# STM32MP153 register map
File version: 1.3
CPU: CM4 r0p1, little endian, no MPU, FPU, 4 interrupt priority bits
Registers are 32-bit, read-write, reset 0x0 unless marked. A register's access mark holds for its fields unless they carry their own. Offsets are from the block's base; [hi:lo] are bit positions; 'fields as' and 'values as' point back to an identical list.

## RCC (part 1 of 2)
Base 0x50000000
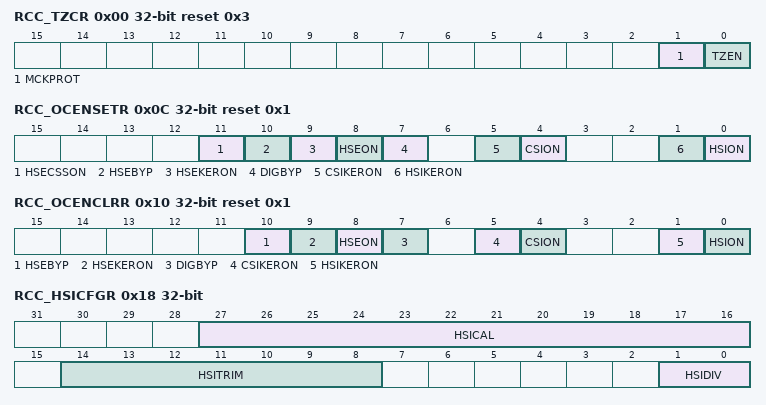
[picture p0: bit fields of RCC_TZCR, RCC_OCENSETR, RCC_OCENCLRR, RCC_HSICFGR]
0x00 RCC_TZCR reset 0x3 — This register is used to switch the RCC into secure mode. This register can only be accessed in secure mode.
  [1] MCKPROT, [0] TZEN
0x0C RCC_OCENSETR reset 0x1 — This register is used to control the oscillators.Writing to this register has no effect, writing will set the corresponding bits. Reading will give the effective values of each bit.If TZEN = MCKPROT = , this register can only be modified in secure mode. Write access to this register is not allowed during the clock restore sequence. See Section: The clock restore sequence description for details.
  [11] HSECSSON, [10] HSEBYP, [9] HSEKERON, [8] HSEON, [7] DIGBYP, [5] CSIKERON, [4] CSION, [1] HSIKERON, [0] HSION
0x10 RCC_OCENCLRR reset 0x1 — This register is used to control the oscillators.Writing to this register has no effect, writing will clear the corresponding bits. Reading will give the effective values of the enable bits.If TZEN = , this register can only be modified in secure mode. Write access to this register is not allowed during the clock restore sequence. See Section: The clock restore sequence description for details.
  [10] HSEBYP, [9] HSEKERON, [8] HSEON, [7] DIGBYP, [5] CSIKERON, [4] CSION, [1] HSIKERON, [0] HSION
0x18 RCC_HSICFGR access per field — This register is used to configure the HSI. If TZEN = , this register can only be modified in secure mode. Write access to this register is not allowed during the clock restore sequence. See Section: The clock restore sequence description for details.
  [27:16] HSICAL ro, [14:8] HSITRIM rw, [1:0] HSIDIV rw
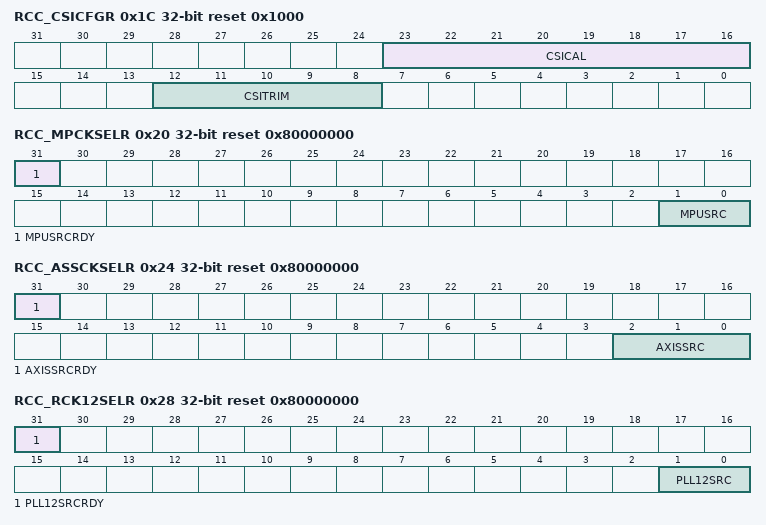
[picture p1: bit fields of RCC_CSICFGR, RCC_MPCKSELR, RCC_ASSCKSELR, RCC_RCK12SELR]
0x1C RCC_CSICFGR access per field reset 0x1000 — This register is used to fine-tune the CSI frequency. If TZEN = MCKPROT = , this register can only be modified in secure mode. Write access to this register is not allowed during the clock restore sequence. See The clock restore sequence description for details.
  [23:16] CSICAL ro, [12:8] CSITRIM rw
0x20 RCC_MPCKSELR access per field reset 0x80000000 — This register is used to select the clock source for the MPU. If TZEN = , this register can only be modified in secure mode. Write access to this register is not allowed during the clock restore sequence. See Section: The clock restore sequence description for details.
  [31] MPUSRCRDY ro, [1:0] MPUSRC rw
0x24 RCC_ASSCKSELR access per field reset 0x80000000 — This register is used to select the clock source for the AXI sub-system. If TZEN = , this register can only be modified in secure mode. Write access to this register is not allowed during the clock restore sequence. See Section: The clock restore sequence description for details.
  [31] AXISSRCRDY ro, [2:0] AXISSRC rw
0x28 RCC_RCK12SELR access per field reset 0x80000000 — This register is used to select the reference clock for PLL1 and PLL2. If TZEN = , this register can only be modified in secure mode. Write access to this register is not allowed during the clock restore sequence. See Section: The clock restore sequence description for details.
  [31] PLL12SRCRDY ro, [1:0] PLL12SRC rw
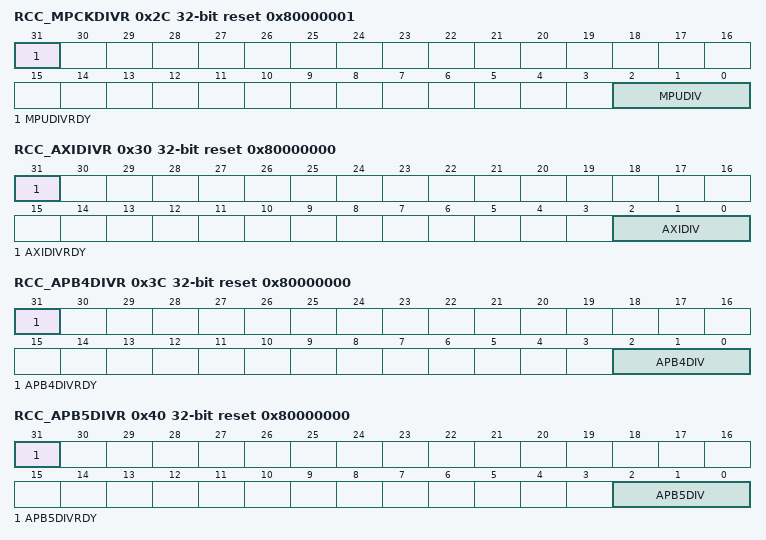
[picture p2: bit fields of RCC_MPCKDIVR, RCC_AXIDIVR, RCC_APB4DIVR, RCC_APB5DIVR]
0x2C RCC_MPCKDIVR access per field reset 0x80000001 — This register is used to control the MPU clock prescaler. Refer to Section: Sub-system clock generation for additional information. If TZEN = , this register can only be modified in secure mode.
  [31] MPUDIVRDY ro, [2:0] MPUDIV rw
0x30 RCC_AXIDIVR access per field reset 0x80000000 — This register is used to control the AXI Matrix clock prescaler. Refer to Section: Sub-system clock generation for additional information. If TZEN = , this register can only be modified in secure mode.
  [31] AXIDIVRDY ro, [2:0] AXIDIV rw
0x3C RCC_APB4DIVR access per field reset 0x80000000 — This register is used to control the APB4 clock divider. Refer to Section: Sub-system clock generation for additional information. If TZEN = , this register can only be modified in secure mode.
  [31] APB4DIVRDY ro, [2:0] APB4DIV rw
0x40 RCC_APB5DIVR access per field reset 0x80000000 — This register is used to control the APB5 clock divider. Refer to Section: Sub-system clock generation for additional information. If TZEN = , this register can only be modified in secure mode.
  [31] APB5DIVRDY ro, [2:0] APB5DIV rw
0x44 RCC_RTCDIVR — This register is used to divide the HSE clock for RTC. If TZEN = , this register can only be modified in secure mode.
  [5:0] RTCDIV
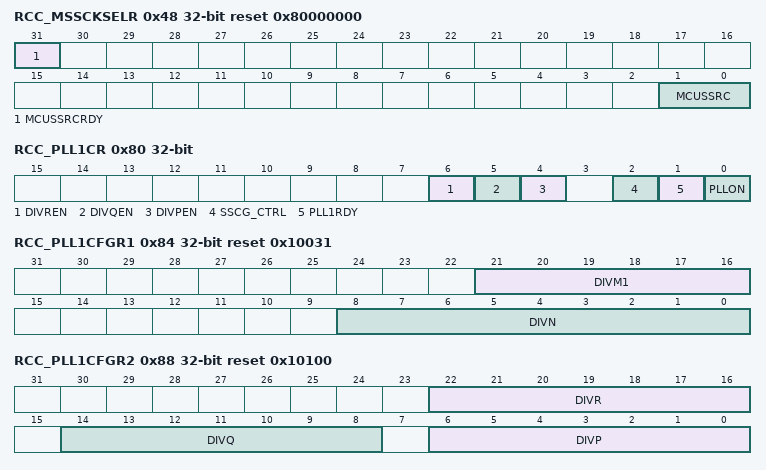
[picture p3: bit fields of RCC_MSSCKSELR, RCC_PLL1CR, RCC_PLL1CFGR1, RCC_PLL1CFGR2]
0x48 RCC_MSSCKSELR access per field reset 0x80000000 — This register is used to select the clock source for the MCU sub-system, including the MCU itself. If TZEN = MCKPROT = , this register can only be modified in secure mode. Write access to this register is not allowed during the clock restore sequence. See Section: The clock restore sequence description for details.
  [31] MCUSSRCRDY ro, [1:0] MCUSSRC rw
0x80 RCC_PLL1CR access per field — This register is used to control the PLL1. If TZEN = , this register can only be modified in secure mode. Write access to this register is not allowed during the clock restore sequence. See Section: The clock restore sequence description for details.
  [6] DIVREN rw, [5] DIVQEN rw, [4] DIVPEN rw, [2] SSCG_CTRL rw, [1] PLL1RDY ro, [0] PLLON rw
0x84 RCC_PLL1CFGR1 reset 0x10031 — This register is used to configure the PLL1. If TZEN = , this register can only be modified in secure mode. Write access to this register is not allowed during the clock restore sequence. See Section: The clock restore sequence description for details.
  [21:16] DIVM1, [8:0] DIVN
0x88 RCC_PLL1CFGR2 reset 0x10100 — This register is used to configure the PLL1. If TZEN = , this register can only be modified in secure mode. Write access to this register is not allowed during the clock restore sequence. See Section: The clock restore sequence description for details.
  [22:16] DIVR, [14:8] DIVQ, [6:0] DIVP
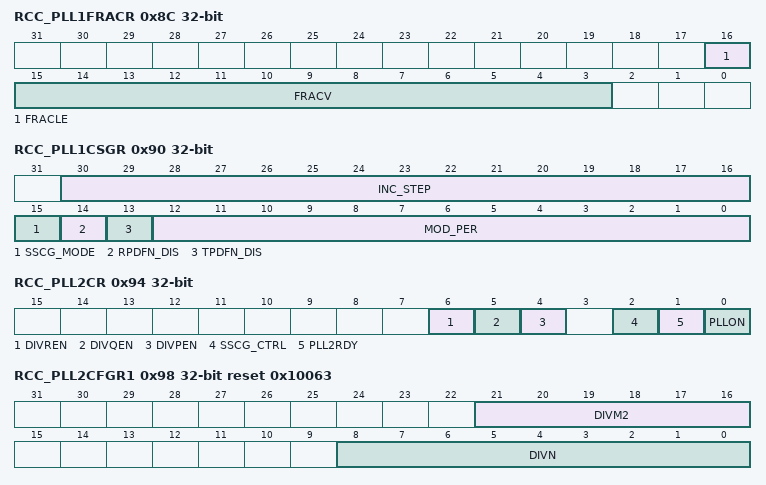
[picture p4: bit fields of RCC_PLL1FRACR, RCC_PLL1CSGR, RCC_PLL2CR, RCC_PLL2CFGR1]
0x8C RCC_PLL1FRACR — This register is used to fine-tune the frequency of the PLL1 VCO. If TZEN = , this register can only be modified in secure mode. Write access to this register is not allowed during the clock restore sequence. See Section: The clock restore sequence description for details.
  [16] FRACLE, [15:3] FRACV
0x90 RCC_PLL1CSGR — This register is used to configure the PLL1.It is not recommended to change the content of this register when the PLL1 is enabled (PLLON = ). Refer to Section: Using the PLLs in spread spectrum mode for details. If TZEN = , this register can only be modified in secure mode. Write access to this register is not allowed during the clock restore sequence. See Section: The clock restore sequence description for details.
  [30:16] INC_STEP, [15] SSCG_MODE, [14] RPDFN_DIS, [13] TPDFN_DIS, [12:0] MOD_PER
0x94 RCC_PLL2CR access per field — This register is used to control the PLL2. If TZEN = , this register can only be modified in secure mode. Write access to this register is not allowed during the clock restore sequence. See Section: The clock restore sequence description for details.
  [6] DIVREN rw, [5] DIVQEN rw, [4] DIVPEN rw, [2] SSCG_CTRL rw, [1] PLL2RDY ro, [0] PLLON rw
0x98 RCC_PLL2CFGR1 reset 0x10063 — This register is used to configure the PLL2. If TZEN = , this register can only be modified in secure mode. Write access to this register is not allowed during the clock restore sequence. See Section: The clock restore sequence description for details.
  [21:16] DIVM2, [8:0] DIVN
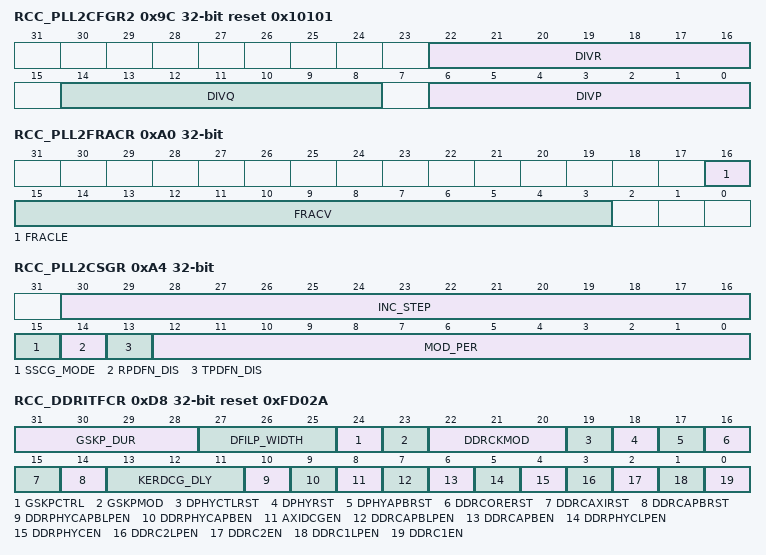
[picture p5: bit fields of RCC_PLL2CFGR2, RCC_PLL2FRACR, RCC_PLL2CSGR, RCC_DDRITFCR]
0x9C RCC_PLL2CFGR2 reset 0x10101 — This register is used to configure the PLL2. If TZEN = , this register can only be modified in secure mode. Write access to this register is not allowed during the clock restore sequence. See Section: The clock restore sequence description for details.
  [22:16] DIVR, [14:8] DIVQ, [6:0] DIVP
0xA0 RCC_PLL2FRACR — This register is used to fine-tune the frequency of the PLL2 VCO. If TZEN = , this register can only be modified in secure mode. Write access to this register is not allowed during the clock restore sequence. See Section: The clock restore sequence description for details.
  [16] FRACLE, [15:3] FRACV
0xA4 RCC_PLL2CSGR — This register is used to configure the PLL2. It is not recommended to change the content of this register when the PLL2 is enabled (PLLON = ). Refer to Section: Using the PLLs in spread spectrum mode for details. If TZEN = , this register can only be modified in secure mode. Write access to this register is not allowed during the clock restore sequence. See Section: The clock restore sequence description for details.
  fields as RCC_PLL1CSGR
0xC0 RCC_I2C46CKSELR — This register is used to control the selection of the kernel clock for the I2C4 and I2C6. Note that changing the clock source on-the-fly is allowed, and will not generate any timing violation, however the user has to ensure that both the previous and the new clock sources are present during the switching, and for the whole transition time. Refer to Section: Clock enabling delays. If TZEN = , this register can only be modified in secure mode.
  [2:0] I2C46SRC
0xC4 RCC_SPI6CKSELR — This register is used to control the selection of the kernel clock for the SPI6. Note that changing the clock source on-the-fly is allowed, and will not generate any timing violation, however the user has to ensure that both the previous and the new clock sources are present during the switching, and for the whole transition time. Refer to Section: Clock enabling delays. If TZEN = , this register can only be modified in secure mode.
  [2:0] SPI6SRC
0xC8 RCC_UART1CKSELR — This register is used to control the selection of the kernel clock for the USART1. Note that changing the clock source on-the-fly is allowed, and will not generate any timing violation, however the user has to ensure that both the previous and the new clock sources are present during the switching, and for the whole transition time. Refer to Section: Clock enabling delays. If TZEN = , this register can only be modified in secure mode.
  [2:0] UART1SRC
0xCC RCC_RNG1CKSELR — This register is used to control the selection of the kernel clock for the RNG1. Note that changing the clock source on-the-fly is allowed, and will not generate any timing violation, however the user has to ensure that both the previous and the new clock sources are present during the switching, and for the whole transition time. Refer to Section: Clock enabling delays. If TZEN = , this register can only be modified in secure mode.
  [1:0] RNG1SRC
0xD0 RCC_CPERCKSELR — This register is used to select an oscillator source as kernel clock for the per_ck clock. The per_ck clock is distributed to several peripherals. Refer to Section: Clock enabling delays.
  [1:0] CKPERSRC
0xD4 RCC_STGENCKSELR — This register is used to select the peripheral clock for the STGEN block. Note that this clock is used to provide a time reference for the application. Refer to Section: Clock enabling delays. If TZEN = , this register can only be modified in secure mode.
  [1:0] STGENSRC
0xD8 RCC_DDRITFCR reset 0xFD02A — This register is used to control the DDR interface, including the DDRC and DDRPHYC. If TZEN = , this register can only be modified in secure mode.
  [31:28] GSKP_DUR, [27:25] DFILP_WIDTH, [24] GSKPCTRL, [23] GSKPMOD, [22:20] DDRCKMOD, [19] DPHYCTLRST, [18] DPHYRST, [17] DPHYAPBRST, [16] DDRCORERST, [15] DDRCAXIRST, [14] DDRCAPBRST, [13:11] KERDCG_DLY, [10] DDRPHYCAPBLPEN, [9] DDRPHYCAPBEN, [8] AXIDCGEN, [7] DDRCAPBLPEN, [6] DDRCAPBEN, [5] DDRPHYCLPEN, [4] DDRPHYCEN, [3] DDRC2LPEN, [2] DDRC2EN, [1] DDRC1LPEN, [0] DDRC1EN
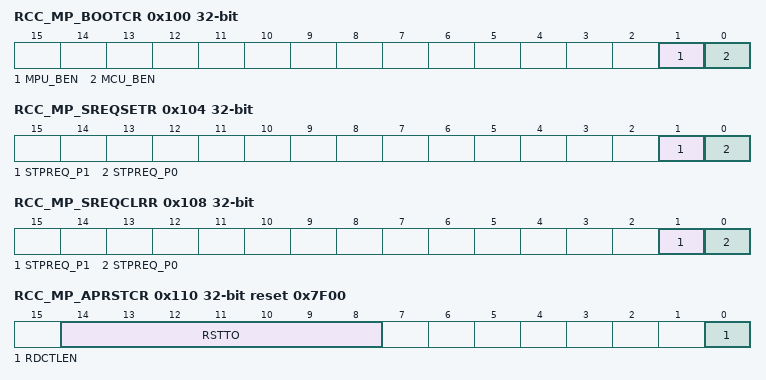
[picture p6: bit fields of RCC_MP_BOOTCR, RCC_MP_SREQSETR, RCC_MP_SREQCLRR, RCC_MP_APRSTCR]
0x100 RCC_MP_BOOTCR — This register is used to control the HOLD boot function when the system exits from Standby. Refer to Section: MCU HOLD_BOOT after processor reset. This register is reset when a system reset occurs, but not when the circuit exits from Standby (app_rst reset).If TZEN = , this register can only be modified in secure mode. This register can only be accessed by the MPU.
  [1] MPU_BEN, [0] MCU_BEN
0x104 RCC_MP_SREQSETR — Writing has no effect, reading will return the values of the bits. Writing a sets the corresponding bit to . The MCU cannot access to this register. If TZEN = , this register can only be modified in secure mode.
  [1] STPREQ_P1, [0] STPREQ_P0
0x108 RCC_MP_SREQCLRR — Writing has no effect, reading will return the effective values of the bits. Writing a sets the corresponding bit to . The MCU cannot access to this register. If TZEN = , this register can only be modified in secure mode.
  [1] STPREQ_P1, [0] STPREQ_P0
0x10C RCC_MP_GCR — The register contains global control bits. If TZEN = , this register can only be modified in secure mode.
  [0] BOOT_MCU
0x110 RCC_MP_APRSTCR reset 0x7F00 — This register is used to control the behavior of the warm reset. If TZEN = , this register can only be modified in secure mode.
  [14:8] RSTTO, [0] RDCTLEN
0x114 RCC_MP_APRSTSR ro — This register provides a status of the RDCTL. If TZEN = , this register can only be modified in secure mode.
  [14:8] RSTTOV
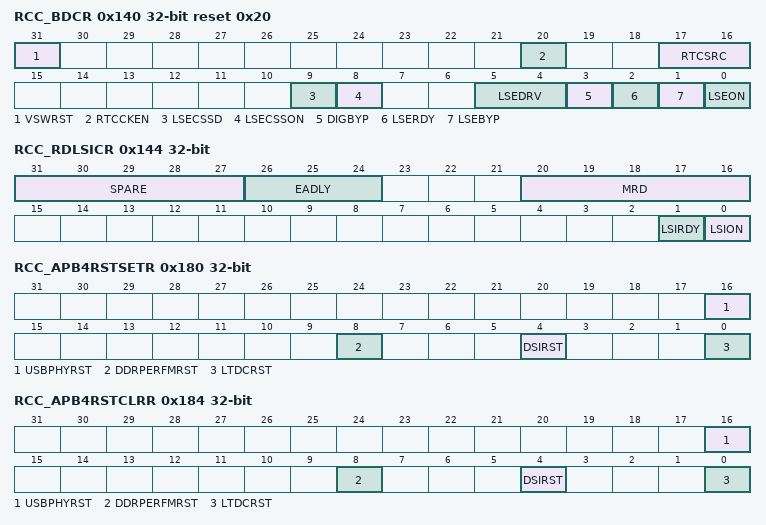
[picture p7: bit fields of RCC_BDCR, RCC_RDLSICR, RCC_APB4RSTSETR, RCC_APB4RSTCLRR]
0x140 RCC_BDCR access per field reset 0x20 — This register is used to control the LSE function. Wait states are inserted in case of successive write accesses to this register. The number of wait states may be up to 7 cycles of AHB4 clock.After a system reset, the register RCC_BDCR is write-protected. In order to modify this register, the DBP bit in the PWR control register 1 (PWR_CR1) has to be set to . Bits of RCC_BDCR register are only reset after a backup domain reset: nreset_vsw (see Section10.3.6: Backup domain reset). Any other internal or external reset will not have any effect on these bits.This register is located into the VSW domain. If TZEN = , this register can only be modified in secure mode.
  [31] VSWRST rw, [20] RTCCKEN rw, [17:16] RTCSRC ro, [9] LSECSSD ro, [8] LSECSSON rw, [5:4] LSEDRV rw, [3] DIGBYP ro, [2] LSERDY ro, [1] LSEBYP rw, [0] LSEON rw
0x144 RCC_RDLSICR access per field — This register is used to control the minimum NRST active duration and LSI function.0 to 7 wait states are inserted for word, half-word and byte accesses. Wait states are inserted in case of successive accesses to this register.This register is reset by the por_rst reset, and it is located into the VDD domain. If TZEN = , this register can only be modified in secure mode.
  [31:27] SPARE rw, [26:24] EADLY rw, [20:16] MRD rw, [1] LSIRDY ro, [0] LSION rw
0x180 RCC_APB4RSTSETR — This register is used to activate the reset of the corresponding peripheral. Writing has no effect, reading will return the effective values of the corresponding bits. Writing a activates the reset of the corresponding peripheral.
  [16] USBPHYRST, [8] DDRPERFMRST, [4] DSIRST, [0] LTDCRST
0x184 RCC_APB4RSTCLRR — This register is used to release the reset of the corresponding peripheral. Writing has no effect, reading will return the effective values of the corresponding bits. Writing a releases the reset of the corresponding peripheral.
  [16] USBPHYRST, [8] DDRPERFMRST, [4] DSIRST, [0] LTDCRST
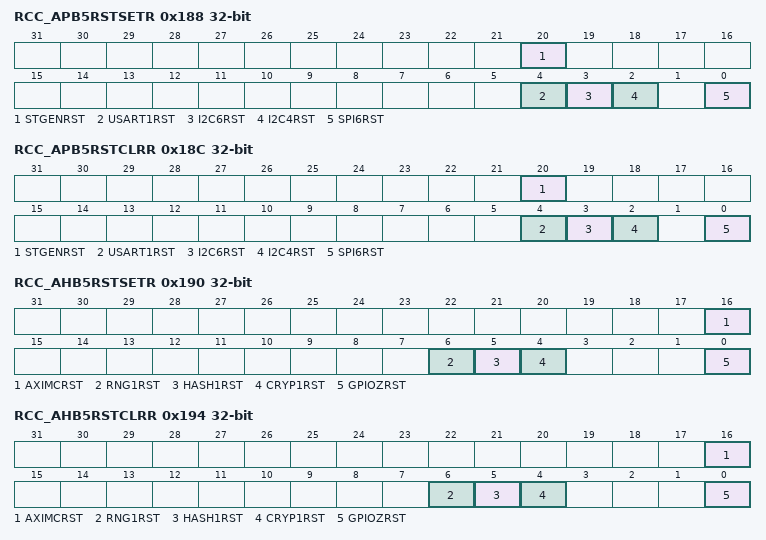
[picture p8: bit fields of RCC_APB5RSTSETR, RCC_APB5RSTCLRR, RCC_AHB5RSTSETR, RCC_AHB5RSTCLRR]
0x188 RCC_APB5RSTSETR — This register is used to activate the reset of the corresponding peripheral. Writing has no effect, reading will return the effective values of the corresponding bits. Writing a activates the reset of the corresponding peripheral. If TZEN = , this register can only be modified in secure mode.
  [20] STGENRST, [4] USART1RST, [3] I2C6RST, [2] I2C4RST, [0] SPI6RST
0x18C RCC_APB5RSTCLRR — This register is used to release the reset of the corresponding peripheral. Writing has no effect, reading will return the effective values of the corresponding bits. Writing a releases the reset of the corresponding peripheral. If TZEN = , this register can only be modified in secure mode.
  [20] STGENRST, [4] USART1RST, [3] I2C6RST, [2] I2C4RST, [0] SPI6RST
0x190 RCC_AHB5RSTSETR — This register is used to activate the reset of the corresponding peripheral. Writing has no effect, reading will return the effective values of the corresponding bits. Writing a activates the reset of the corresponding peripheral. If TZEN = , this register can only be modified in secure mode.
  [16] AXIMCRST, [6] RNG1RST, [5] HASH1RST, [4] CRYP1RST, [0] GPIOZRST
0x194 RCC_AHB5RSTCLRR — This register is used to release the reset of the corresponding peripheral. Writing has no effect, reading will return the effective values of the corresponding bits. Writing a releases the reset of the corresponding peripheral. If TZEN = , this register can only be modified in secure mode.
  [16] AXIMCRST, [6] RNG1RST, [5] HASH1RST, [4] CRYP1RST, [0] GPIOZRST
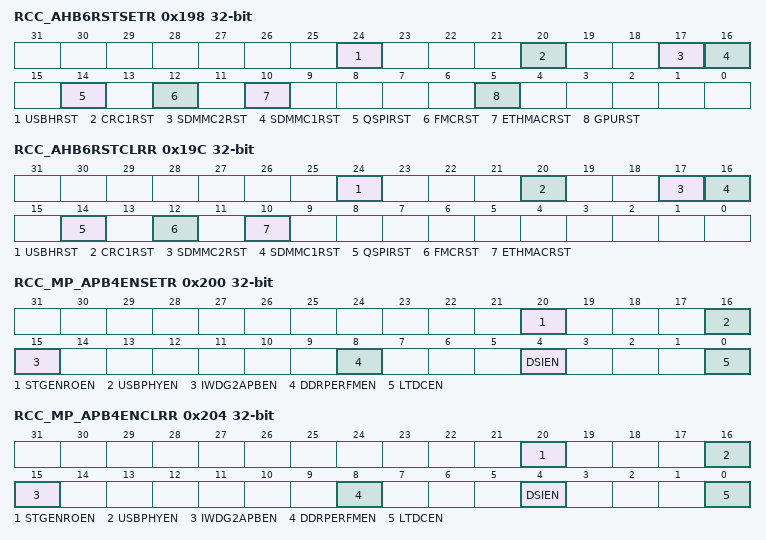
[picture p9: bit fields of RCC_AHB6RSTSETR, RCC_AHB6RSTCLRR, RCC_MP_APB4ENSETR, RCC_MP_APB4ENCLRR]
0x198 RCC_AHB6RSTSETR — This register is used to activate the reset of the corresponding peripheral. Writing has no effect, reading will return the effective values of the corresponding bits. Writing a activates the reset of the corresponding peripheral.
  [24] USBHRST, [20] CRC1RST, [17] SDMMC2RST, [16] SDMMC1RST, [14] QSPIRST, [12] FMCRST, [10] ETHMACRST, [5] GPURST
0x19C RCC_AHB6RSTCLRR — This register is used to release the reset of the corresponding peripheral. Writing has no effect, reading will return the effective values of the corresponding bits. Writing a releases the reset of the corresponding peripheral.
  [24] USBHRST, [20] CRC1RST, [17] SDMMC2RST, [16] SDMMC1RST, [14] QSPIRST, [12] FMCRST, [10] ETHMACRST
0x1A0 RCC_TZAHB6RSTSETR — This register is used to activate the reset of the corresponding peripheral. Writing has no effect, reading will return the effective values of the corresponding bits. Writing a activates the reset of the corresponding peripheral. If TZEN = , this register can only be modified in secure mode.
  [0] MDMARST
0x1A4 RCC_TZAHB6RSTCLRR — This register is used to release the reset of the corresponding peripheral. Writing has no effect, reading will return the effective values of the corresponding bits. Writing a releases the reset of the corresponding peripheral. If TZEN = , this register can only be modified in secure mode.
  [0] MDMARST
0x200 RCC_MP_APB4ENSETR — This register is used to set the peripheral clock enable bit of the corresponding peripheral to . It shall be used to allocate a peripheral to the MPU. Writing has no effect, reading will return the effective values of the corresponding bits. Writing a sets the corresponding bit to .
  [20] STGENROEN, [16] USBPHYEN, [15] IWDG2APBEN, [8] DDRPERFMEN, [4] DSIEN, [0] LTDCEN
0x204 RCC_MP_APB4ENCLRR — This register is used to clear the peripheral clock enable bit of the corresponding peripheral. It shall be used to deallocate a peripheral from MPU. Writing has no effect, reading will return the effective values of the corresponding bits. Writing a sets the corresponding bit to .
  fields as RCC_MP_APB4ENSETR
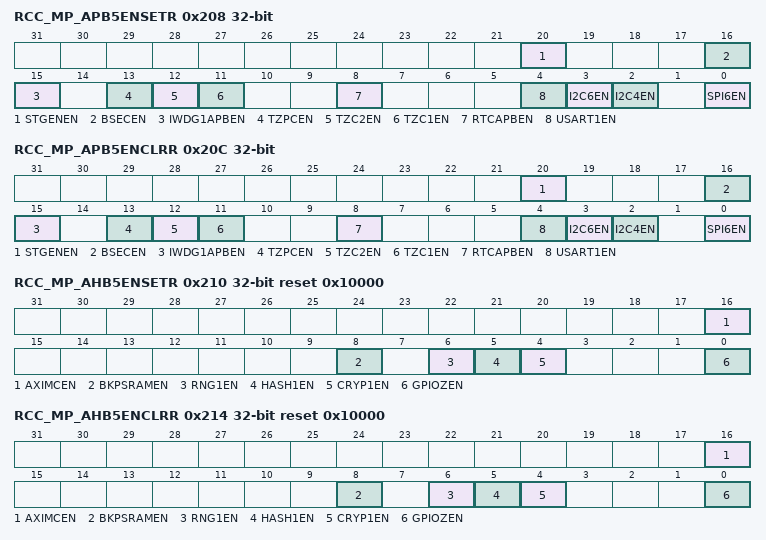
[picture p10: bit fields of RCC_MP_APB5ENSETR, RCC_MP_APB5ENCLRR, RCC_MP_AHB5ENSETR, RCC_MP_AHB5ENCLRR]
0x208 RCC_MP_APB5ENSETR — This register is used to set the peripheral clock enable bit of the corresponding peripheral to . It shall be used to allocate a peripheral to the MPU. Writing has no effect, reading will return the effective values of the corresponding bits. Writing a sets the corresponding bit to .
  [20] STGENEN, [16] BSECEN, [15] IWDG1APBEN, [13] TZPCEN, [12] TZC2EN, [11] TZC1EN, [8] RTCAPBEN, [4] USART1EN, [3] I2C6EN, [2] I2C4EN, [0] SPI6EN
0x20C RCC_MP_APB5ENCLRR — This register is used to clear the peripheral clock enable bit of the corresponding peripheral. It shall be used to deallocate a peripheral from MPU. Writing has no effect, reading will return the effective values of the corresponding bits. Writing a sets the corresponding bit to .
  fields as RCC_MP_APB5ENSETR
0x210 RCC_MP_AHB5ENSETR reset 0x10000 — This register is used to set the peripheral clock enable bit of the corresponding peripheral to . It shall be used to allocate a peripheral to the MPU. Writing has no effect, reading will return the effective values of the corresponding bits. Writing a sets the corresponding bit to . If TZEN = , this register can only be modified in secure mode.
  [16] AXIMCEN, [8] BKPSRAMEN, [6] RNG1EN, [5] HASH1EN, [4] CRYP1EN, [0] GPIOZEN
0x214 RCC_MP_AHB5ENCLRR reset 0x10000 — This register is used to clear the peripheral clock enable bit of the corresponding peripheral. It shall be used to deallocate a peripheral from MPU. Writing has no effect, reading will return the effective values of the corresponding bits. Writing a sets the corresponding bit to . If TZEN = , this register can only be modified in secure mode.
  fields as RCC_MP_AHB5ENSETR
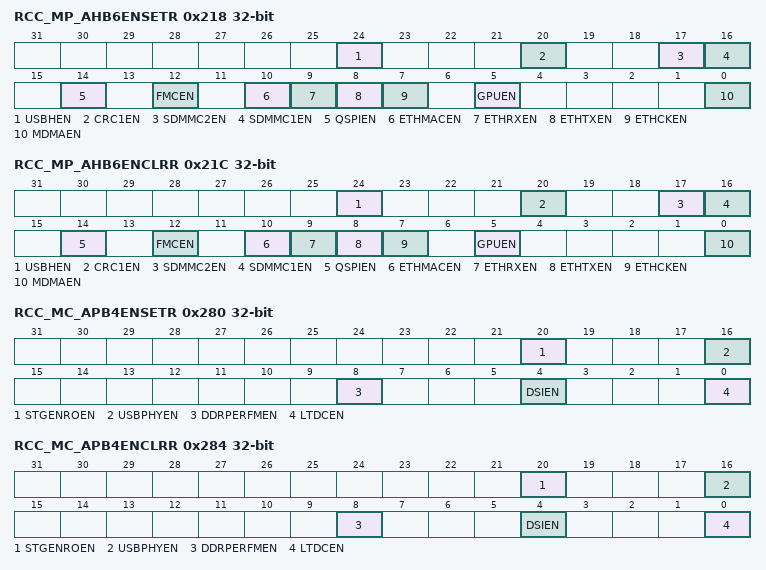
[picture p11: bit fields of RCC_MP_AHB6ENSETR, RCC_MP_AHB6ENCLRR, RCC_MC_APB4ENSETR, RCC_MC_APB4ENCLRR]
0x218 RCC_MP_AHB6ENSETR — This register is used to set the peripheral clock enable bit of the corresponding peripheral to . It shall be used to allocate a peripheral to the MPU. Writing has no effect, reading will return the effective values of the corresponding bits. Writing a sets the corresponding bit to .
  [24] USBHEN, [20] CRC1EN, [17] SDMMC2EN, [16] SDMMC1EN, [14] QSPIEN, [12] FMCEN, [10] ETHMACEN, [9] ETHRXEN, [8] ETHTXEN, [7] ETHCKEN, [5] GPUEN, [0] MDMAEN
0x21C RCC_MP_AHB6ENCLRR — This register is used to clear the peripheral clock enable bit of the corresponding peripheral. It shall be used to deallocate a peripheral from MPU. Writing has no effect, reading will return the effective values of the corresponding bits. Writing a sets the corresponding bit to .
  fields as RCC_MP_AHB6ENSETR
0x220 RCC_MP_TZAHB6ENSETR — This register is used to set the peripheral clock enable bit of the corresponding peripheral to . It shall be used to allocate a peripheral to the MPU. Writing has no effect, reading will return the effective values of the corresponding bits. Writing a sets the corresponding bit to . If TZEN = , this register can only be modified in secure mode.
  [0] MDMAEN
0x224 RCC_MP_TZAHB6ENCLRR — This register is used to clear the peripheral clock enable bit of the corresponding peripheral. It shall be used to deallocate a peripheral from MPU. Writing has no effect, reading will return the effective values of the corresponding bits. Writing a sets the corresponding bit to . If TZEN = , this register can only be modified in secure mode.
  [0] MDMAEN
0x280 RCC_MC_APB4ENSETR — This register is used to set the peripheral clock enable bit
  [20] STGENROEN, [16] USBPHYEN, [8] DDRPERFMEN, [4] DSIEN, [0] LTDCEN
0x284 RCC_MC_APB4ENCLRR — This register is used to clear the peripheral clock enable bit
  [20] STGENROEN, [16] USBPHYEN, [8] DDRPERFMEN, [4] DSIEN, [0] LTDCEN
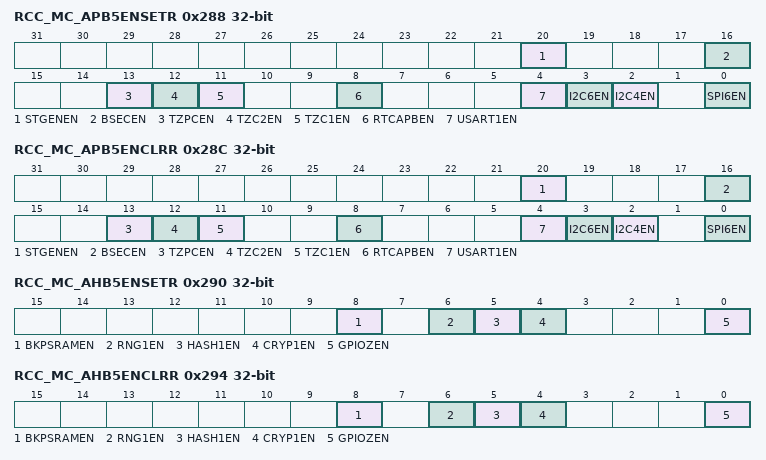
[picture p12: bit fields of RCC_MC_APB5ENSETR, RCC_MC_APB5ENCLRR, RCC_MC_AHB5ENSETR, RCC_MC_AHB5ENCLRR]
0x288 RCC_MC_APB5ENSETR — This register is used to set the peripheral clock enable bit
  [20] STGENEN, [16] BSECEN, [13] TZPCEN, [12] TZC2EN, [11] TZC1EN, [8] RTCAPBEN, [4] USART1EN, [3] I2C6EN, [2] I2C4EN, [0] SPI6EN
0x28C RCC_MC_APB5ENCLRR — This register is used to clear the peripheral clock enable bit
  fields as RCC_MC_APB5ENSETR
0x290 RCC_MC_AHB5ENSETR — This register is used to set the peripheral clock enable bit If TZEN = , this register can only be modified in secure mode.
  [8] BKPSRAMEN, [6] RNG1EN, [5] HASH1EN, [4] CRYP1EN, [0] GPIOZEN
0x294 RCC_MC_AHB5ENCLRR — This register is used to clear the peripheral clock enable bit If TZEN = , this register can only be modified in secure mode.
  [8] BKPSRAMEN, [6] RNG1EN, [5] HASH1EN, [4] CRYP1EN, [0] GPIOZEN
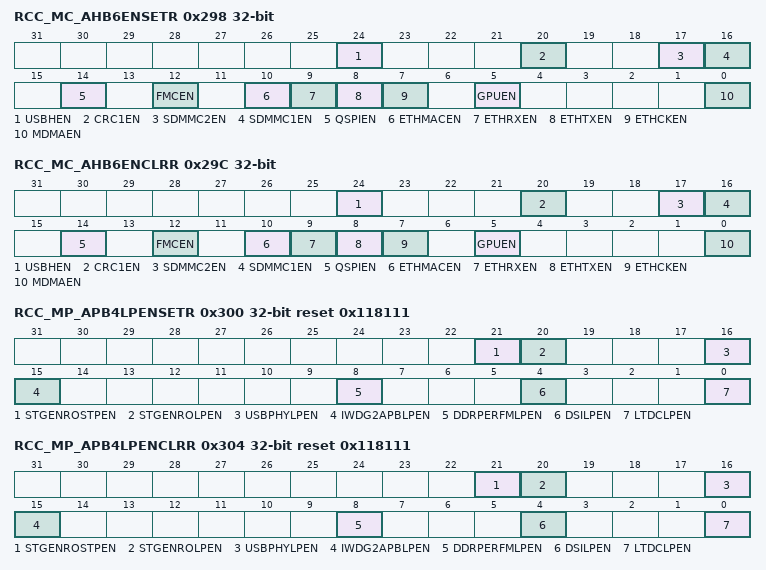
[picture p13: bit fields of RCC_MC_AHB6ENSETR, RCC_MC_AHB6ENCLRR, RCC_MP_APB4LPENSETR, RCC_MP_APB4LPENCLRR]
0x298 RCC_MC_AHB6ENSETR — This register is used to set the peripheral clock enable bit
  fields as RCC_MP_AHB6ENSETR
0x29C RCC_MC_AHB6ENCLRR — This register is used to clear the peripheral clock enable bit
  fields as RCC_MP_AHB6ENSETR
0x300 RCC_MP_APB4LPENSETR reset 0x118111 — This register is used by the MCU in order to clear the PERxLPEN bits
  [21] STGENROSTPEN, [20] STGENROLPEN, [16] USBPHYLPEN, [15] IWDG2APBLPEN, [8] DDRPERFMLPEN, [4] DSILPEN, [0] LTDCLPEN
0x304 RCC_MP_APB4LPENCLRR reset 0x118111 — This register is used by the MCU
  fields as RCC_MP_APB4LPENSETR
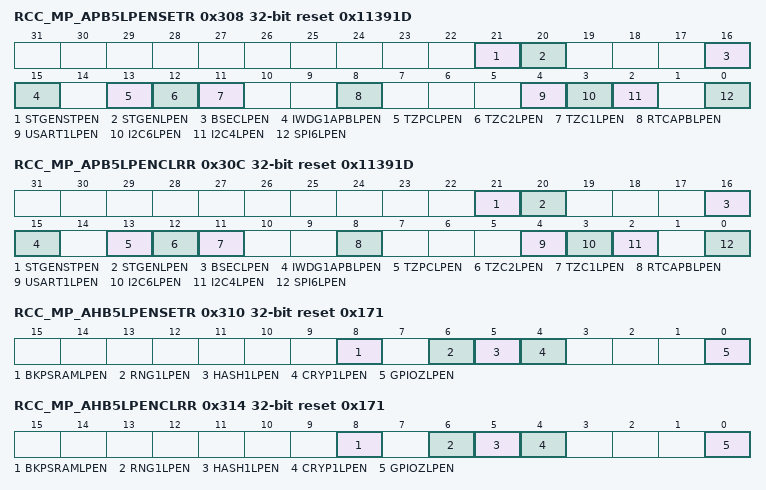
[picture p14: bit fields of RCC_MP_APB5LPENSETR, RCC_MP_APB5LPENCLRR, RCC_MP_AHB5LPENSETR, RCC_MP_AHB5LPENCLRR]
0x308 RCC_MP_APB5LPENSETR reset 0x11391D — This register is used by the MCU in order to clear the PERxLPEN bits If TZEN = , this register can only be modified in secure mode.
  [21] STGENSTPEN, [20] STGENLPEN, [16] BSECLPEN, [15] IWDG1APBLPEN, [13] TZPCLPEN, [12] TZC2LPEN, [11] TZC1LPEN, [8] RTCAPBLPEN, [4] USART1LPEN, [3] I2C6LPEN, [2] I2C4LPEN, [0] SPI6LPEN
0x30C RCC_MP_APB5LPENCLRR reset 0x11391D — This register is used by the Mpu.
  fields as RCC_MP_APB5LPENSETR
0x310 RCC_MP_AHB5LPENSETR reset 0x171 — This register is used by the MCU in order to clear the PERxLPEN bits If TZEN = , this register can only be modified in secure mode.
  [8] BKPSRAMLPEN, [6] RNG1LPEN, [5] HASH1LPEN, [4] CRYP1LPEN, [0] GPIOZLPEN
0x314 RCC_MP_AHB5LPENCLRR reset 0x171 — This register is used by the MCU
  fields as RCC_MP_AHB5LPENSETR
0x318 RCC_MP_AHB6LPENSETR reset 0x11357A1 — This register is used by the MCU in order to clear the PERxLPEN bits
  [24] USBHLPEN, [20] CRC1LPEN, [17] SDMMC2LPEN, [16] SDMMC1LPEN, [14] QSPILPEN, [12] FMCLPEN, [11] ETHSTPEN, [10] ETHMACLPEN, [9] ETHRXLPEN, [8] ETHTXLPEN, [7] ETHCKLPEN, [5] GPULPEN, [0] MDMALPEN
0x31C RCC_MP_AHB6LPENCLRR reset 0x11357A1 — This register is used by the MCU in order to clear the PERxLPEN bits
  fields as RCC_MP_AHB6LPENSETR
0x320 RCC_MP_TZAHB6LPENSETR reset 0x1 — This register is used by the MCU in order to clear the PERxLPEN bits If TZEN = , this register can only be modified in secure mode.
  [0] MDMALPEN
0x324 RCC_MP_TZAHB6LPENCLRR reset 0x1 — This register is used by the MCU in order to clear the PERxLPEN bits If TZEN = , this register can only be modified in secure mode.
  [0] MDMALPEN
0x380 RCC_MC_APB4LPENSETR reset 0x110111 — This register is used by the MCU in order to set the PERxLPEN bit.
  [21] STGENROSTPEN, [20] STGENROLPEN, [16] USBPHYLPEN, [8] DDRPERFMLPEN, [4] DSILPEN, [0] LTDCLPEN
0x384 RCC_MC_APB4LPENCLRR reset 0x110111 — This register is used by the MCU in order to clear the PERxLPEN bit
  fields as RCC_MC_APB4LPENSETR
0x388 RCC_MC_APB5LPENSETR reset 0x11391D — This register is used by the MCU in order to set the PERxLPEN bit.
  [21] STGENSTPEN, [20] STGENLPEN, [16] BSECLPEN, [13] TZPCLPEN, [12] TZC2LPEN, [11] TZC1LPEN, [8] RTCAPBLPEN, [4] USART1LPEN, [3] I2C6LPEN, [2] I2C4LPEN, [0] SPI6LPEN
0x38C RCC_MC_APB5LPENCLRR reset 0x11391D — This register is used by the MCU in order to clear the PERxLPEN bit
  fields as RCC_MC_APB5LPENSETR
0x390 RCC_MC_AHB5LPENSETR reset 0x171 — This register is used by the MCU in order to set the PERxLPEN bit. If TZEN = , this register can only be modified in secure mode.
  fields as RCC_MP_AHB5LPENSETR
0x394 RCC_MC_AHB5LPENCLRR reset 0x171 — This register is used by the MCU in order to clear the PERxLPEN bit If TZEN = , this register can only be modified in secure mode.
  fields as RCC_MP_AHB5LPENSETR
0x398 RCC_MC_AHB6LPENSETR reset 0x11357A1 — This register is used by the MCU in order to set the PERxLPEN bit.
  fields as RCC_MP_AHB6LPENSETR
0x39C RCC_MC_AHB6LPENCLRR reset 0x11357A1 — This register is used by the MCU in order to clear the PERxLPEN bit
  fields as RCC_MP_AHB6LPENSETR
0x400 RCC_BR_RSTSCLRR reset 0x15 — This register is used by the BOOTROM to check the reset source. Writing has no effect, reading will return the effective values of the corresponding bits. Writing a clears the corresponding bit to . In order to identify the reset source, the MPU application must use RCC MPU Reset Status Clear Register (RCC_MP_RSTSCLRR), and the MCU application must use the RCC MCU Reset Status Clear Register (RCC_MC_RSTSCLRR). Refer to Section10.3.13: Reset source identification for details.This register except MPUP[1:0]RSTF flags is located into VDD domain, and is reset by por_rst reset. The MPUP[1:0]RSTF flags are located into VDDCORE and are reset by nreset. If TZEN = , this register can only be modified in secure mode.
  [14] MPUP1RSTF, [13] MPUP0RSTF, [9] IWDG2RSTF, [8] IWDG1RSTF, [7] MCSYSRSTF, [6] MPSYSRSTF, [4] VCORERSTF, [3] HCSSRSTF, [2] PADRSTF, [1] BORRSTF, [0] PORRSTF
0x404 RCC_MP_GRSTCSETR — This register is used by the MPU in order to generate either a MCU reset or a system reset or a reset of one of the two MPU processors. Writing has no effect, reading returns the effective values of the corresponding bits. Writing a activates the reset.
  [5] MPUP1RST, [4] MPUP0RST, [1] MCURST, [0] MPSYSRST
0x408 RCC_MP_RSTSCLRR — This register is used by the MPU to check the reset source. This register is updated by the BOOTROM code, after a power-on reset (por_rst), a system reset (nreset), or an exit from Standby or CStandby.Writing has no effect, reading will return the effective values of the corresponding bits. Writing a clears the corresponding bit to .Refer to Section10.3.13: Reset source identification for details.The register is located in VDDCORE.If TZEN = , this register can only be modified in secure mode.
  [15] SPARE, [14] MPUP1RSTF, [13] MPUP0RSTF, [12] CSTDBYRSTF, [11] STDBYRSTF, [9] IWDG2RSTF, [8] IWDG1RSTF, [7] MCSYSRSTF, [6] MPSYSRSTF, [4] VCORERSTF, [3] HCSSRSTF, [2] PADRSTF, [1] BORRSTF, [0] PORRSTF
0x40C RCC_MP_IWDGFZSETR — This register is used by the BOOTROM in order to freeze the IWDGs clocks. After a system reset or Standby reset (nreset), or a CStandby reset (cstby_rst) the MPU is allowed to write it once.Writing has no effect, reading will return the effective values of the corresponding bits. Writing a sets the corresponding bit to . If TZEN = , this register can only be modified in secure mode.
  [1] FZ_IWDG2, [0] FZ_IWDG1
0x410 RCC_MP_IWDGFZCLRR — This register is used by the BOOTROM in order to unfreeze the IWDGs clocks. Writing has no effect, reading will return the effective values of the corresponding bits. Writing a clears the corresponding bit to . If TZEN = , this register can only be modified in secure mode.
  [1] FZ_IWDG2, [0] FZ_IWDG1
